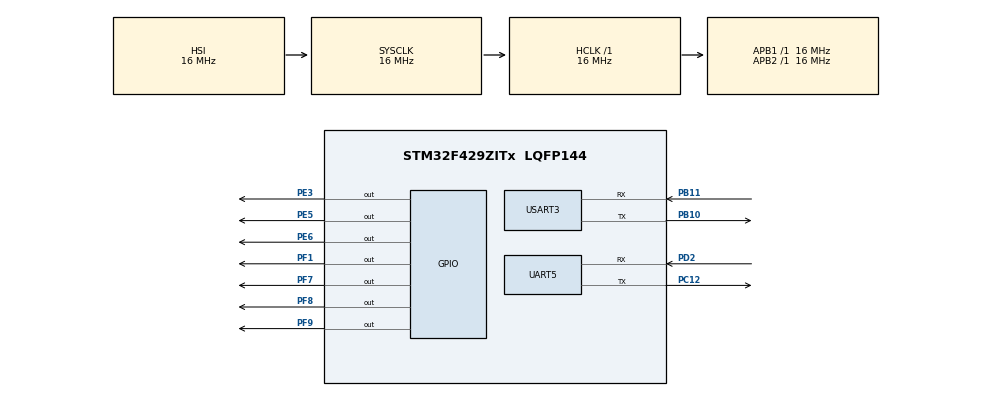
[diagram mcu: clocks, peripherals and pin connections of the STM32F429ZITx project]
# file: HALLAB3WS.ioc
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Mcu.Family=STM32F4
Mcu.Name=STM32F429ZITx
Mcu.Package=LQFP144
NVIC.PriorityGroup=NVIC_PRIORITYGROUP_4
NVIC.UART5_IRQn=true\:0\:0\:false\:false\:true\:true\:true\:true
NVIC.USART3_IRQn=true\:0\:0\:false\:false\:true\:true\:true\:true
PB10.Mode=Asynchronous
PB10.Signal=USART3_TX
PB11.Mode=Asynchronous
PB11.Signal=USART3_RX
PC12.Mode=Asynchronous
PC12.Signal=UART5_TX
PD2.Mode=Asynchronous
PD2.Signal=UART5_RX
PE3.Signal=GPIO_Output
PE5.Signal=GPIO_Output
PE6.Signal=GPIO_Output
PF1.Signal=GPIO_Output
PF7.Signal=GPIO_Output
PF8.Signal=GPIO_Output
PF9.Signal=GPIO_Output
ProjectManager.HeapSize=0x200
ProjectManager.StackSize=0x400
ProjectManager.TargetToolchain=MDK-ARM V5
RCC.AHBFreq_Value=16000000
RCC.APB1Freq_Value=16000000
RCC.APB2Freq_Value=16000000
RCC.CortexFreq_Value=16000000
RCC.HSE_VALUE=25000000
RCC.HSI_VALUE=16000000
RCC.LSE_VALUE=32768
RCC.SYSCLKFreq_VALUE=16000000
RCC.VCOOutputFreq_Value=192000000
UART5.VirtualMode=Asynchronous
USART3.VirtualMode=VM_ASYNC
board=custom

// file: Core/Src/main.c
/* USER CODE BEGIN Header */
/**
  ******************************************************************************
  * @file           : main.c
  * @brief          : Main program body
  ******************************************************************************
  * @attention
  *
  * Copyright (c) 2024 STMicroelectronics.
  * All rights reserved.
  *
  * This software is licensed under terms that can be found in the LICENSE file
  * in the root directory of this software component.
  * If no LICENSE file comes with this software, it is provided AS-IS.
  *
  ******************************************************************************
  */
/* USER CODE END Header */
#include "main.h"
#include "LCD.h"

/* USER CODE BEGIN PM */
uint8_t dataRX[2];
float RXcat;
/* USER CODE END PM */

UART_HandleTypeDef huart5;
UART_HandleTypeDef huart3;

void SystemClock_Config(void);
static void MX_GPIO_Init(void);
static void MX_UART5_Init(void);
static void MX_USART3_UART_Init(void);

int main(void)
{

  /* MCU Configuration--------------------------------------------------------*/

  /* Reset of all peripherals, Initializes the Flash interface and the Systick. */
  HAL_Init();

  /* Configure the system clock */
  SystemClock_Config();

  /* Initialize all configured peripherals */
  MX_GPIO_Init();
  MX_UART5_Init();
  MX_USART3_UART_Init();
  /* USER CODE BEGIN 2 */
LCD_setup();
LCD_send_String("Initialised");
LCD_clear();
  /* USER CODE END 2 */

  /* Infinite loop */
  while (1)
  {

    /* USER CODE BEGIN 3 */
		LCD_clear();

		RXcat = 0;
		/*
LCD_send_intString(dataRX[0]);
LCD_send_String(".");
LCD_send_intString(dataRX[1]);
*/

		HAL_UART_Receive( &huart5, dataRX, 2, 2000);
		// concatenate
		RXcat = (dataRX[0] << 8);
		RXcat = RXcat + dataRX[1];
		RXcat = RXcat/10;
		LCD_send_floatString(RXcat);
		HAL_Delay(700);
  }
  /* USER CODE END 3 */
}

void SystemClock_Config(void)
{
  RCC_OscInitTypeDef RCC_OscInitStruct = {0};
  RCC_ClkInitTypeDef RCC_ClkInitStruct = {0};

  /** Configure the main internal regulator output voltage
  */
  __HAL_RCC_PWR_CLK_ENABLE();
  __HAL_PWR_VOLTAGESCALING_CONFIG(PWR_REGULATOR_VOLTAGE_SCALE3);

  /** Initializes the RCC Oscillators according to the specified parameters
  * in the RCC_OscInitTypeDef structure.
  */
  RCC_OscInitStruct.OscillatorType = RCC_OSCILLATORTYPE_HSI;
  RCC_OscInitStruct.HSIState = RCC_HSI_ON;
  RCC_OscInitStruct.HSICalibrationValue = RCC_HSICALIBRATION_DEFAULT;
  RCC_OscInitStruct.PLL.PLLState = RCC_PLL_NONE;
  if (HAL_RCC_OscConfig(&RCC_OscInitStruct) != HAL_OK)
  {
    Error_Handler();
  }

  /** Initializes the CPU, AHB and APB buses clocks
  */
  RCC_ClkInitStruct.ClockType = RCC_CLOCKTYPE_HCLK|RCC_CLOCKTYPE_SYSCLK
                              |RCC_CLOCKTYPE_PCLK1|RCC_CLOCKTYPE_PCLK2;
  RCC_ClkInitStruct.SYSCLKSource = RCC_SYSCLKSOURCE_HSI;
  RCC_ClkInitStruct.AHBCLKDivider = RCC_SYSCLK_DIV1;
  RCC_ClkInitStruct.APB1CLKDivider = RCC_HCLK_DIV1;
  RCC_ClkInitStruct.APB2CLKDivider = RCC_HCLK_DIV1;

  if (HAL_RCC_ClockConfig(&RCC_ClkInitStruct, FLASH_LATENCY_0) != HAL_OK)
  {
    Error_Handler();
  }
}

static void MX_UART5_Init(void)
{

  huart5.Instance = UART5;
  huart5.Init.BaudRate = 115200;
  huart5.Init.WordLength = UART_WORDLENGTH_8B;
  huart5.Init.StopBits = UART_STOPBITS_1;
  huart5.Init.Parity = UART_PARITY_NONE;
  huart5.Init.Mode = UART_MODE_TX_RX;
  huart5.Init.HwFlowCtl = UART_HWCONTROL_NONE;
  huart5.Init.OverSampling = UART_OVERSAMPLING_16;
  if (HAL_UART_Init(&huart5) != HAL_OK)
  {
    Error_Handler();
  }

}

static void MX_USART3_UART_Init(void)
{

  huart3.Instance = USART3;
  huart3.Init.BaudRate = 115200;
  huart3.Init.WordLength = UART_WORDLENGTH_8B;
  huart3.Init.StopBits = UART_STOPBITS_1;
  huart3.Init.Parity = UART_PARITY_NONE;
  huart3.Init.Mode = UART_MODE_TX_RX;
  huart3.Init.HwFlowCtl = UART_HWCONTROL_NONE;
  huart3.Init.OverSampling = UART_OVERSAMPLING_16;
  if (HAL_UART_Init(&huart3) != HAL_OK)
  {
    Error_Handler();
  }

}

static void MX_GPIO_Init(void)
{
  GPIO_InitTypeDef GPIO_InitStruct = {0};

  /* GPIO Ports Clock Enable */
  __HAL_RCC_GPIOE_CLK_ENABLE();
  __HAL_RCC_GPIOF_CLK_ENABLE();
  __HAL_RCC_GPIOB_CLK_ENABLE();
  __HAL_RCC_GPIOC_CLK_ENABLE();
  __HAL_RCC_GPIOD_CLK_ENABLE();

  /*Configure GPIO pin Output Level */
  HAL_GPIO_WritePin(GPIOE, GPIO_PIN_3|GPIO_PIN_5|GPIO_PIN_6, GPIO_PIN_RESET);

  /*Configure GPIO pin Output Level */
  HAL_GPIO_WritePin(GPIOF, GPIO_PIN_1|GPIO_PIN_7|GPIO_PIN_8|GPIO_PIN_9, GPIO_PIN_RESET);

  /*Configure GPIO pins : PE3 PE5 PE6 */
  GPIO_InitStruct.Pin = GPIO_PIN_3|GPIO_PIN_5|GPIO_PIN_6;
  GPIO_InitStruct.Mode = GPIO_MODE_OUTPUT_PP;
  GPIO_InitStruct.Pull = GPIO_NOPULL;
  GPIO_InitStruct.Speed = GPIO_SPEED_FREQ_LOW;
  HAL_GPIO_Init(GPIOE, &GPIO_InitStruct);

  /*Configure GPIO pins : PF1 PF7 PF8 PF9 */
  GPIO_InitStruct.Pin = GPIO_PIN_1|GPIO_PIN_7|GPIO_PIN_8|GPIO_PIN_9;
  GPIO_InitStruct.Mode = GPIO_MODE_OUTPUT_PP;
  GPIO_InitStruct.Pull = GPIO_NOPULL;
  GPIO_InitStruct.Speed = GPIO_SPEED_FREQ_LOW;
  HAL_GPIO_Init(GPIOF, &GPIO_InitStruct);

}

void Error_Handler(void)
{
  __disable_irq();
  while (1)
  {
  }
}
